# VPAC0_COMMON_0_IVPAC_TOP_0_CFG_SLV_DRU_UTC_VPAC0_DRU_MMR_CFG_DRU_DRU_CHRT register map
Vendor: Texas Instruments
Peripheral module from a debugger description file (folder am62A).
Registers are 64-bit, read-only, reset 0x0 unless marked. A register's access mark holds for its fields unless they carry their own. Offsets are as the file gives them; lines under a group give offsets from that group; [hi:lo] are bit positions; {n}, {i} and the like mark numbered series; 'fields as' and 'values as' point back to an identical list; <NAME> marks a mode.

## VPAC0_COMMON_0_IVPAC_TOP_0_CFG_SLV_DRU_UTC_VPAC0_DRU_MMR_CFG_DRU_DRU_CHRT
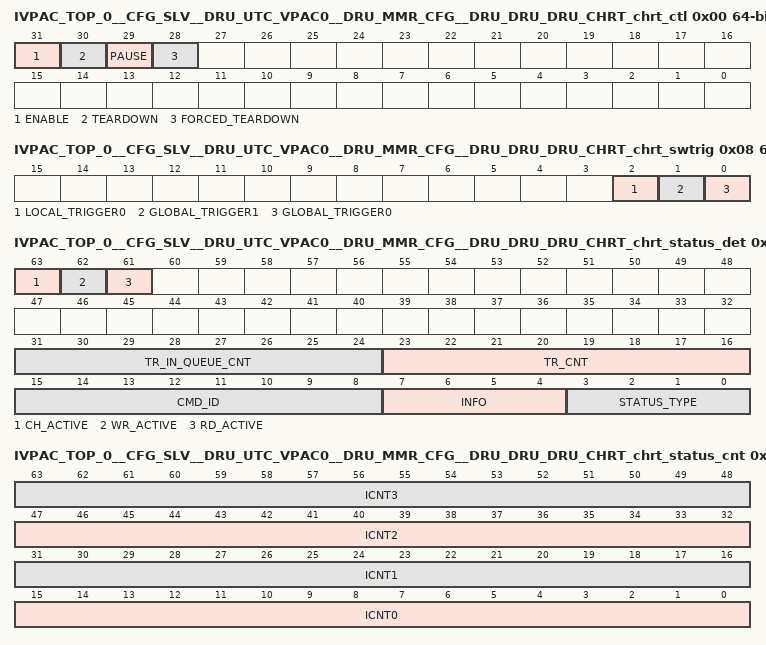
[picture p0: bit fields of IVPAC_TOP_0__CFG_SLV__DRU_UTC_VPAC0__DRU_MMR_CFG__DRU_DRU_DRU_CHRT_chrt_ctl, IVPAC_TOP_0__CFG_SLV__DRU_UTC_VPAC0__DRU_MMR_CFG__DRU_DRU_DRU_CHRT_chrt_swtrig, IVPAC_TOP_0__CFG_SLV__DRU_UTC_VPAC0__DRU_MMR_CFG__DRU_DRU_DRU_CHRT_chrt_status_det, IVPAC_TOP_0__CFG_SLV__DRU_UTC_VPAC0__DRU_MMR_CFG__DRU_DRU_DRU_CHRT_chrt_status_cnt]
0x00 IVPAC_TOP_0__CFG_SLV__DRU_UTC_VPAC0__DRU_MMR_CFG__DRU_DRU_DRU_CHRT_chrt_ctl rw — The channel realtime control register contains real-time cotrol and status information for the DMA Channel. The fields in this regsiter can be changed while the channel is in operation.
  [31] ENABLE — This field enables or disables the channel. Disabling a channel halts operation on the channel after the current block transfer is completed. Disabling a channel in the middle of a packet transfer may result in underflow conditions in the attached application block and data loss. This field is encoded as follows: 0 = channel is disabled 1 = channel is enabled This field will be cleared after a channel teardown is complete.
  [30] TEARDOWN — Channel teardown: Setting this bit will request the channel to be torn down. This field will remain set after a channel teardown is complete.
  [29] PAUSE — Channel pause: Setting this bit will request the channel to pause processing at the next packet boundary. This is a more graceful method of halting processing than disabling the channel as it will not allow any current packets to underflow.
  [28] FORCED_TEARDOWN — Channel forced teardown: Setting this bit will request the channel to be torn down forcefulyy. This field will clear after a channel teardown is complete.
0x08 IVPAC_TOP_0__CFG_SLV__DRU_UTC_VPAC0__DRU_MMR_CFG__DRU_DRU_DRU_CHRT_chrt_swtrig rw — The Software Trigger Register provides a mechanism by which software can directly trigger the channel in a secure way.
  [2] LOCAL_TRIGGER0 — Trigger: writing this bit with a value of 1 will cause the trigger event to be sent to this channel. This will trigger LOCAL Event
  [1] GLOBAL_TRIGGER1 — Trigger: writing this bit with a value of 1 will cause the trigger event to be sent to this channel. This will trigger Global Event 1
  [0] GLOBAL_TRIGGER0 — Trigger: writing this bit with a value of 1 will cause the trigger event to be sent to this channel. This will trigger Global Event 0
0x10 IVPAC_TOP_0__CFG_SLV__DRU_UTC_VPAC0__DRU_MMR_CFG__DRU_DRU_DRU_CHRT_chrt_status_det — The channel status details
  [63] CH_ACTIVE — The channel has some active work
  [62] WR_ACTIVE — The top TR has submitted a sub-TR to the write portion of the queue
  [61] RD_ACTIVE — The top TR has submitted a sub-TR to the read portion of the queue
  [31:24] TR_IN_QUEUE_CNT — The number of TRs for the channel that are in the queue FIFO
  [23:16] TR_CNT — The number of TRs in the channel FIFO
  [15:8] CMD_ID — The last cmd_id given to the write queue
  [7:4] INFO — The info of the error that was received
  [3:0] STATUS_TYPE — The type of error that was received
0x18 IVPAC_TOP_0__CFG_SLV__DRU_UTC_VPAC0__DRU_MMR_CFG__DRU_DRU_DRU_CHRT_chrt_status_cnt — The channel count details
  [16n+15:16n] ICNT{n} (n=0..3) — The last icnt{n} given to the write queue
0x20 IVPAC_TOP_0__CFG_SLV__DRU_UTC_VPAC0__DRU_MMR_CFG__DRU_DRU_DRU_CHRT_chrt_ring_fwd_db wo — The Ring N Doorbell Register is written by software to increment or decrement the number of entries on a Ring. One or more entries as specified by the entry_cnt field can be added to a ring with a single write operation.
  [7:0] ENTRY_CNT — Signed number of entries by which to increment the ring occupancy. For normal Tx Ring operation, this value should be a positive number. This occ value for the ring is increased by this value each time the doorbell register is written (occ absolute value will increase or decrease based on the sign of the tentry_cnt).
0x28 IVPAC_TOP_0__CFG_SLV__DRU_UTC_VPAC0__DRU_MMR_CFG__DRU_DRU_DRU_CHRT_chrt_ring_fwd_occ — The Ring N Occupancy Register can be read by software to determine the total number of valid entries on a ring. The contents of each of these registers are unary ORed in order to create a pending signal for the ring which can be used for triggering hardware operations and/or for generating interrupts to the host.
  [16:0] OCC — Total number of valid entries on the ring. This value is generally intended to be incremented by doorbell pokes from software and is decremented by the DMA engine as entries are completed.
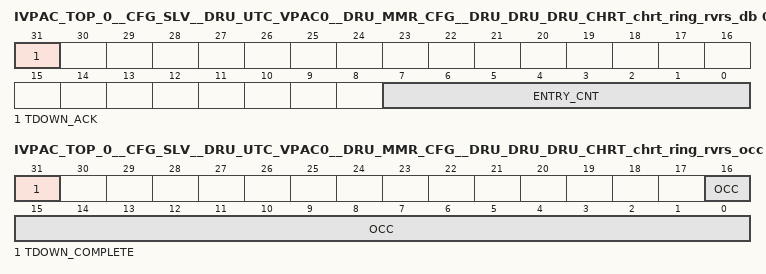
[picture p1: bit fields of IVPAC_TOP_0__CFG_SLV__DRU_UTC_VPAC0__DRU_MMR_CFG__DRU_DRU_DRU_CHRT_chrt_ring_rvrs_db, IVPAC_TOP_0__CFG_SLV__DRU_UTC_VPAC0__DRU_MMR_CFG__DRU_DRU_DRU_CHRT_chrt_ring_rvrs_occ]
0x40 IVPAC_TOP_0__CFG_SLV__DRU_UTC_VPAC0__DRU_MMR_CFG__DRU_DRU_DRU_CHRT_chrt_ring_rvrs_db wo — The Ring N Doorbell Register is written by software to increment or decrement the number of entries on a Ring. One or more entries as specified by the entry_cnt field can be added to a ring with a single write operation.
  [31] TDOWN_ACK — This bit is set to 1 to ackowledge (and clear) the tdown_complete bit in the corresponding Ring N Occupancy Register. this bit is only valid on the reverse rings (rings consumed by the Host SW)
  [7:0] ENTRY_CNT — Signed number of entries by which to increment the ring occupancy. For normal Tx Ring operation, this value should be a positive number. This occ value for the ring is increased by this value each time the doorbell register is written (occ absolute value will increase or decrease based on the sign of the tentry_cnt).
0x48 IVPAC_TOP_0__CFG_SLV__DRU_UTC_VPAC0__DRU_MMR_CFG__DRU_DRU_DRU_CHRT_chrt_ring_rvrs_occ — The Ring N Occupancy Register can be read by software to determine the total number of valid entries on a ring. The contents of each of these registers are unary ORed in order to create a pending signal for the ring which can be used for triggering hardware operations and/or for generating interrupts to the host.
  [31] TDOWN_COMPLETE — This bit when set indicates that a teardown is complete on the channel. This bit is cleared anytime the tdown_ack bit is written as a 1 in the corresponding Ring N Doorbell Register. This bit is only valid on the reverse rings (rings consumed by the Host SW).
  [16:0] OCC — Total number of valid entries on the ring. This value is generally intended to be incremented by doorbell pokes from software and is decremented by the DMA engine as entries are completed.
